# CY8C5888LTI_LP097 register map
File version: 0.1
CY8C58LP
Registers are 8-bit, read-write, no defined reset value unless marked. A register's access mark holds for its fields unless they carry their own. Offsets are from the block's base; lines under a group give offsets from that group; [hi:lo] are bit positions; {n}, {i} and the like mark numbered series; 'fields as' and 'values as' point back to an identical list; <NAME> marks a mode.

## Memory map
0x00000000 uart_rpi — UART
0x00000000 weight_adc — SAR ADC
0x00000000 pump_timer_1
0x00000000 pump_timer_2
0x00000000 check_weight_timer
0x00000000 pump_timer_3

## uart_rpi — UART
Base 0x00000000
0x40006421 RX_uart_rpi_RX_ADDRESS1 — RX Address1 Register
0x40006431 RX_uart_rpi_RX_ADDRESS2 — RX Address2 Register
0x40006440 TX_uart_rpi_TX_DATA — TX Data Register
0x40006441 RX_uart_rpi_RX_DATA — RX Data Register
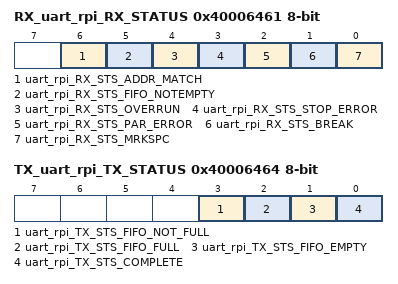
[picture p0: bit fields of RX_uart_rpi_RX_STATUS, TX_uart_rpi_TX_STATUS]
0x40006461 RX_uart_rpi_RX_STATUS — RX status register
  [6] uart_rpi_RX_STS_ADDR_MATCH ro, [5] uart_rpi_RX_STS_FIFO_NOTEMPTY ro, [4] uart_rpi_RX_STS_OVERRUN ro, [3] uart_rpi_RX_STS_STOP_ERROR ro, [2] uart_rpi_RX_STS_PAR_ERROR ro, [1] uart_rpi_RX_STS_BREAK ro, [0] uart_rpi_RX_STS_MRKSPC ro
0x40006464 TX_uart_rpi_TX_STATUS — TX status register
  [3] uart_rpi_TX_STS_FIFO_NOT_FULL ro, [2] uart_rpi_TX_STS_FIFO_FULL ro, [1] uart_rpi_TX_STS_FIFO_EMPTY ro, [0] uart_rpi_TX_STS_COMPLETE ro

## weight_adc — SAR ADC
Base 0x00000000
0x40004616 SAR_TR0 — SAR trim register
{0x40005908+i} SAR_CSR{i} (i=0..6) — SAR status and control register {i}
0x40005B28 SAR_SW0 — SAR Analog Routing Register 0
{0x40005B28+i} SAR_SW{i} (i=2..4) — SAR Analog Routing Register {i}
0x40005B2E SAR_SW6 — SAR Analog Routing Register 6
0x40005B2F SAR_CLK — SAR Clock Selection Register
0x40005BA2 SAR_WRK 16-bit — SAR working register

## pump_timer_1
Base 0x00000000
0x40006405 pump_timer_1_COUNTER 24-bit — UDB.A0 - Current Down Counter Value
0x40006425 pump_timer_1_PERIOD 24-bit — UDB.D0 - Assigned Period
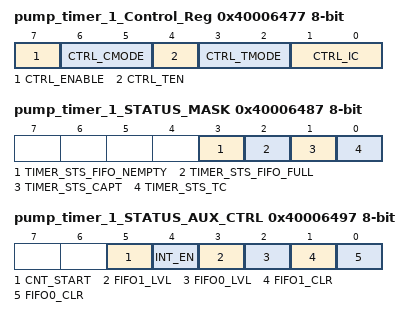
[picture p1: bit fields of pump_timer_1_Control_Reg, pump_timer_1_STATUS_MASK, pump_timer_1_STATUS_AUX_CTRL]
0x40006477 pump_timer_1_Control_Reg — UDB Control Register - Assigned Control Register Value
  [7] CTRL_ENABLE — Enable the Timer
  [6:5] CTRL_CMODE — Capture Mode
  [4] CTRL_TEN — Trigger Enable Bit
  [3:2] CTRL_TMODE — Trigger Mode
  [1:0] CTRL_IC — Interrupt Count
0x40006487 pump_timer_1_STATUS_MASK — UDB Status bits Interrupt Mask Enable Register
  [3] TIMER_STS_FIFO_NEMPTY ro — FIFO Empty status
  [2] TIMER_STS_FIFO_FULL ro — FIFO Full Status
  [1] TIMER_STS_CAPT ro — Enables the Interrupt on Capture
  [0] TIMER_STS_TC ro — Enables the Interrupt on TC
0x40006497 pump_timer_1_STATUS_AUX_CTRL — UDB Auxilliary Control Register
  [5] CNT_START — FIFO0 clear
    0=E_CNT_START0 (Disable counter); 1=E_CNT_START1 (Enable counter)
  [4] INT_EN
    0=E_INT_EN0 (Interrupt disabled); 1=E_INT_EN1 (Interrupt enabled)
  [3] FIFO1_LVL — FIFO level
    0=E_FIFO_LVL_0 (FIFO LVL: input mode: FIFO not full; output mode: FIFO not empty); 1=E_FIFO_LVL_1 (FIFO LVL: input mode: FIFO at least 1/2 empty; output mode: FIFO at least 1/2 full)
  [2] FIFO0_LVL — FIFO level
    values as FIFO1_LVL
  [1] FIFO1_CLR — FIFO1 clear
    0=E_FIFO_CLR_0 (Normal FIFO operation); 1=E_FIFO_CLR_1 (Clear FIFO state)
  [0] FIFO0_CLR — FIFO0 clear
    values as FIFO1_CLR

## pump_timer_2
Base 0x00000000
0x40006504 pump_timer_2_COUNTER 24-bit — UDB.A0 - Current Down Counter Value
0x40006524 pump_timer_2_PERIOD 24-bit — UDB.D0 - Assigned Period
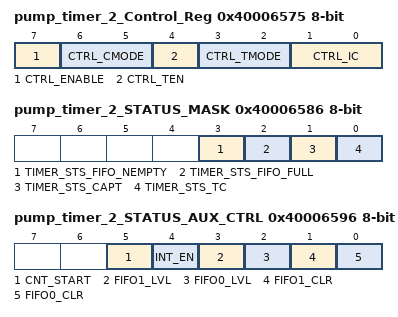
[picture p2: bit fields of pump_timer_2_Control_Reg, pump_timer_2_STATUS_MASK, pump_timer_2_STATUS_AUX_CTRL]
0x40006575 pump_timer_2_Control_Reg — UDB Control Register - Assigned Control Register Value
  [7] CTRL_ENABLE — Enable the Timer
  [6:5] CTRL_CMODE — Capture Mode
  [4] CTRL_TEN — Trigger Enable Bit
  [3:2] CTRL_TMODE — Trigger Mode
  [1:0] CTRL_IC — Interrupt Count
0x40006586 pump_timer_2_STATUS_MASK — UDB Status bits Interrupt Mask Enable Register
  [3] TIMER_STS_FIFO_NEMPTY ro — FIFO Empty status
  [2] TIMER_STS_FIFO_FULL ro — FIFO Full Status
  [1] TIMER_STS_CAPT ro — Enables the Interrupt on Capture
  [0] TIMER_STS_TC ro — Enables the Interrupt on TC
0x40006596 pump_timer_2_STATUS_AUX_CTRL — UDB Auxilliary Control Register
  [5] CNT_START — FIFO0 clear
    0=E_CNT_START0 (Disable counter); 1=E_CNT_START1 (Enable counter)
  [4] INT_EN
    0=E_INT_EN0 (Interrupt disabled); 1=E_INT_EN1 (Interrupt enabled)
  [3] FIFO1_LVL — FIFO level
    0=E_FIFO_LVL_0 (FIFO LVL: input mode: FIFO not full; output mode: FIFO not empty); 1=E_FIFO_LVL_1 (FIFO LVL: input mode: FIFO at least 1/2 empty; output mode: FIFO at least 1/2 full)
  [2] FIFO0_LVL — FIFO level
    values as FIFO1_LVL
  [1] FIFO1_CLR — FIFO1 clear
    0=E_FIFO_CLR_0 (Normal FIFO operation); 1=E_FIFO_CLR_1 (Clear FIFO state)
  [0] FIFO0_CLR — FIFO0 clear
    values as FIFO1_CLR
